# apollo1 register map
Vendor: Ambiq Micro, Inc.; Series: Apollo; File version: 1.0
Ultra-Low power ARM Cortex-M4 MCU from Ambiq Micro
CPU: CM4 r1p0, little endian, MPU, FPU, 3 interrupt priority bits
Registers are 32-bit, read-write, reset 0x0 unless marked. A register's access mark holds for its fields unless they carry their own. Offsets are from the block's base; lines under a group give offsets from that group; [hi:lo] are bit positions; {n}, {i} and the like mark numbered series; 'fields as' and 'values as' point back to an identical list; <NAME> marks a mode.

## Memory map
0x40000000 RSTGEN size 0x210 — MCU Reset Generator
0x40004000 CLKGEN size 0x110 — Clock Generator
0x40004040 RTC size 0xD0 — Real Time Clock
0x40008000 CTIMER size 0x210 — Counter/Timer
0x4000C000 VCOMP size 0x210 — Voltage Comparator
0x40010000 GPIO size 0x220 — General Purpose IO
0x4001C000 UART size 0x48 — Serial UART
0x40020000 MCUCTRL size 0x254 — MCU Miscellaneous Control Logic
0x40024000 WDT size 0x210 — Watchdog Timer
0x50000000 IOSLAVE size 0x220 — I2C/SPI Slave
0x50004000 IOMSTR0 size 0x210 — I2C/SPI Master
0x50005000 IOMSTR1 size 0x210
0x50008000 ADC size 0x210 — Analog Digital Converter Control

## Interrupts
0 BROWNOUT (MCUCTRL)
1 WDT
2 CLKGEN_RTC (CLKGEN)
3 VCOMP
4 IOSLAVE
5 IOSLAVEACC (IOSLAVE)
6 IOMSTR0
7 IOMSTR1
8 ADC
9 GPIO
10 CTIMER
11 UART

## IOSLAVE — I2C/SPI Slave
Base 0x50000000
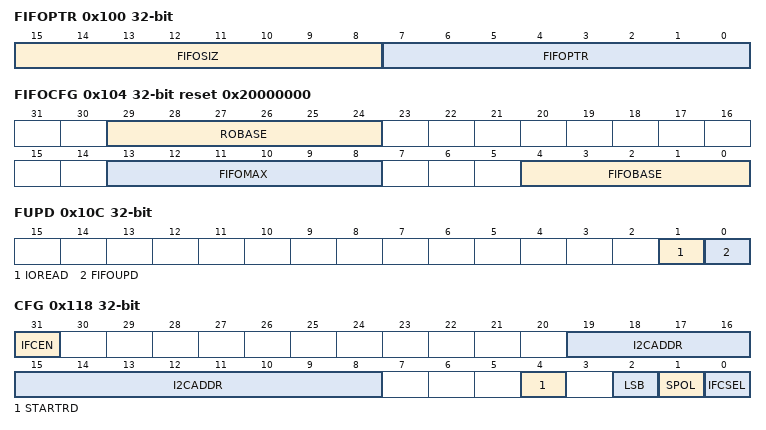
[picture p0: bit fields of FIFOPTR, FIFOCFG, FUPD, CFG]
0x100 FIFOPTR — Current FIFO Pointer
  [15:8] FIFOSIZ — The number of bytes currently in the hardware FIFO.
  [7:0] FIFOPTR — Current FIFO pointer.
0x104 FIFOCFG reset 0x20000000 — FIFO Configuration
  [29:24] ROBASE — Defines the read-only area. The IO Slave read-only area is situated in LRAM at (ROBASE*8) to (FIFOOBASE*8-1)
  [13:8] FIFOMAX — These bits hold the maximum FIFO address in 8 byte segments. It is also the beginning of the RAM area of the LRAM. Note that no RAM area is configured if FIFOMAX is set to 0x1F.
  [4:0] FIFOBASE — These bits hold the base address of the I/O FIFO in 8 byte segments. The IO Slave FIFO is situated in LRAM at (FIFOBASE*8) to (FIFOMAX*8-1).
0x108 FIFOTHR — FIFO Threshold Configuration
  [7:0] FIFOTHR — FIFO size interrupt threshold.
0x10C FUPD — FIFO Update Status
  [1] IOREAD — This bitfield indicates an IO read is active.
  [0] FIFOUPD — This bit indicates that a FIFO update is underway.
0x110 FIFOCTR — Overall FIFO Counter
  [9:0] FIFOCTR — Virtual FIFO byte count
0x114 FIFOINC — Overall FIFO Counter Increment
  [9:0] FIFOINC — Increment the Overall FIFO Counter by this value on a write
0x118 CFG — I/O Slave Configuration
  [31] IFCEN — IOSLAVE interface enable.
    0=DIS (Disable the IOSLAVE); 1=EN (Enable the IOSLAVE)
  [19:8] I2CADDR — 7-bit or 10-bit I2C device address.
  [4] STARTRD — This bit holds the cycle to initiate an I/O RAM read.
    0=LATE (Initiate I/O RAM read late in each transferred byte.); 1=EARLY (Initiate I/O RAM read early in each transferred byte.)
  [2] LSB — This bit selects the transfer bit ordering.
    0=MSB_FIRST (Data is assumed to be sent and received with MSB first.); 1=LSB_FIRST (Data is assumed to be sent and received with LSB first.)
  [1] SPOL — This bit selects SPI polarity.
    0=SPI_MODES_0_3 (Polarity 0, handles SPI modes 0 and 3.); 1=SPI_MODES_1_2 (Polarity 1, handles SPI modes 1 and 2.)
  [0] IFCSEL — This bit selects the I/O interface.
    0=I2C (Selects I2C interface for the IO Slave.); 1=SPI (Selects SPI interface for the IO Slave.)
0x11C PRENC — I/O Slave Interrupt Priority Encode
  [4:0] PRENC — These bits hold the priority encode of the REGACC interrupts.
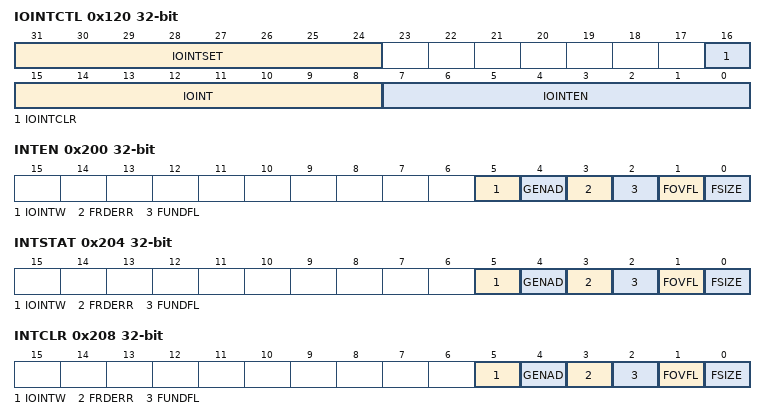
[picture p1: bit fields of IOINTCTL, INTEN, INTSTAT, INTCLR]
0x120 IOINTCTL — I/O Interrupt Control
  [31:24] IOINTSET — These bits set the IOINT interrupts when written with a 1.
  [16] IOINTCLR — This bit clears all of the IOINT interrupts when written with a 1.
  [15:8] IOINT — These bits read the IOINT interrupts.
  [7:0] IOINTEN — These bits setread the IOINT interrupt enables.
0x124 GENADD — General Address Data
  [7:0] GADATA — The data supplied on the last General Address reference.
0x200 INTEN — IO Slave Interrupts: Enable
  [5] IOINTW — I2C Interrupt Write interrupt.
  [4] GENAD — I2C General Address interrupt.
  [3] FRDERR — FIFO Read Error interrupt.
  [2] FUNDFL — FIFO Underflow interrupt.
  [1] FOVFL — FIFO Overflow interrupt.
  [0] FSIZE — FIFO Size interrupt.
0x204 INTSTAT — IO Slave Interrupts: Status
  fields as INTEN
0x208 INTCLR — IO Slave Interrupts: Clear
  fields as INTEN
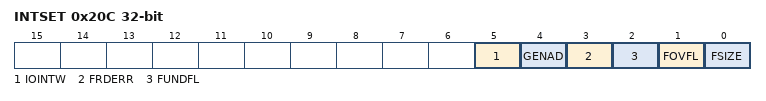
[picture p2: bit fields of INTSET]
0x20C INTSET — IO Slave Interrupts: Set
  fields as INTEN
0x210 REGACCINTEN — Register Access Interrupts: Enable
  [31:0] REGACC — Register access interrupts.
0x214 REGACCINTSTAT — Register Access Interrupts: Status
  [31:0] REGACC — Register access interrupts.
0x218 REGACCINTCLR — Register Access Interrupts: Clear
  [31:0] REGACC — Register access interrupts.
0x21C REGACCINTSET — Register Access Interrupts: Set
  [31:0] REGACC — Register access interrupts.

## Licence text in the file
Copyright (c) 2020, Ambiq Micro. All rights reserved. . Redistribution and use in source and binary forms, with or without modification, are permitted provided that the following conditions are met: . 1. Redistributions of source code must retain the above copyright notice, this list of conditions and the following disclaimer. . 2. Redistributions in binary form must reproduce the above copyright notice, this list of conditions and the following disclaimer in the documentation and/or other materials provided with the distribution. . 3. Neither the name of the copyright holder nor the names of its contributors may be used to endorse or promote products derived from this software without specific prior written permission. . Third party software included in this distribution is subject to the additional license terms as defined in the /docs/licenses directory. . THIS SOFTWARE IS PROVIDED BY THE COPYRIGHT HOLDERS AND CONTRIBUTORS "AS IS" AND ANY EXPRESS OR IMPLIED WARRANTIES, INCLUDING, BUT NOT LIMITED TO, THE. IMPLIED WARRANTIES OF MERCHANTABILITY AND FITNESS FOR A PARTICULAR PURPOSE. ARE DISCLAIMED. IN NO EVENT SHALL THE COPYRIGHT HOLDER OR CONTRIBUTORS BE. LIABLE FOR ANY DIRECT, INDIRECT, INCIDENTAL, SPECIAL, EXEMPLARY, OR. CONSEQUENTIAL DAMAGES (INCLUDING, BUT NOT LIMITED TO, PROCUREMENT OF. SUBSTITUTE GOODS OR SERVICES; LOSS OF USE, DATA, OR PROFITS; OR BUSINESS. INTERRUPTION) HOWEVER CAUSED AND ON ANY THEORY OF LIABILITY, WHETHER IN. CONTRACT, STRICT LIABILITY, OR TORT (INCLUDING NEGLIGENCE OR OTHERWISE). ARISING IN ANY WAY OUT OF THE USE OF THIS SOFTWARE, EVEN IF ADVISED OF THE. POSSIBILITY OF SUCH DAMAGE.

## Notices in the file
Copyright (C) 2012-2014 ARM Limited. All rights reserved.
Purpose: System Viewer Description (SVD) Example (Schema Version 1.1)
This is a description of a none-existent and incomplete device
for demonstration purposes only.
- Neither the name of ARM nor the names of its contributors may be used
ARE DISCLAIMED. IN NO EVENT SHALL COPYRIGHT HOLDERS AND CONTRIBUTORS BE
